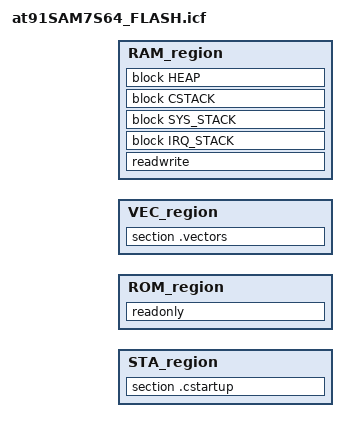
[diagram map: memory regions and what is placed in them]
/*###ICF### Section handled by ICF editor, don't touch! ****/
/*-Editor annotation file-*/
/* IcfEditorFile="$TOOLKIT_DIR$\config\ide\IcfEditor\a_v1_0.xml" */
/*-Specials-*/
define symbol __ICFEDIT_intvec_start__ = 0x00000000;
/*-Memory Regions-*/
define symbol __ICFEDIT_region_ROM_start__   = 0x100000;
define symbol __ICFEDIT_region_ROM_end__     = 0x10FFFF;
define symbol __ICFEDIT_region_RAM_start__ = 0x00200000;
define symbol __ICFEDIT_region_RAM_end__   = 0x00203FFF;
/*-Sizes-*/
define symbol __ICFEDIT_size_cstack__   = 0x200;
define symbol __ICFEDIT_size_svcstack__ = 0x200;
define symbol __ICFEDIT_size_irqstack__ = 0x200;
define symbol __ICFEDIT_size_fiqstack__ = 0x4;
define symbol __ICFEDIT_size_undstack__ = 0x4;
define symbol __ICFEDIT_size_abtstack__ = 0x4;
define symbol __ICFEDIT_size_heap__     = 0x4;
/*-Exports-*/
export symbol __ICFEDIT_region_ROM_start__;
export symbol __ICFEDIT_region_ROM_end__;
export symbol __ICFEDIT_region_RAM_start__;
export symbol __ICFEDIT_region_RAM_end__;
export symbol __ICFEDIT_size_startup__;
export symbol __ICFEDIT_size_vectors__;
export symbol __ICFEDIT_size_cstack__;
export symbol __ICFEDIT_size_sysstack__;
export symbol __ICFEDIT_size_irqstack__;
export symbol __ICFEDIT_size_heap__;
/**** End of ICF editor section. ###ICF###*/


define memory mem with size = 4G;
define region STA_region = mem:[from __ICFEDIT_region_ROM_start__ size __ICFEDIT_size_startup__];
define region ROM_region = mem:[from __ICFEDIT_region_ROM_start__+__ICFEDIT_size_startup__ to __ICFEDIT_region_ROM_end__];
define region VEC_region = mem:[from __ICFEDIT_region_RAM_start__ size __ICFEDIT_size_vectors__];
define region RAM_region = mem:[from __ICFEDIT_region_RAM_start__+__ICFEDIT_size_vectors__ to __ICFEDIT_region_RAM_end__];

define block CSTACK    with alignment = 8, size = __ICFEDIT_size_cstack__   { };
define block SYS_STACK with alignment = 8, size = __ICFEDIT_size_sysstack__ { };
define block IRQ_STACK with alignment = 8, size = __ICFEDIT_size_irqstack__ { };
define block HEAP      with alignment = 8, size = __ICFEDIT_size_heap__     { };

initialize by copy { readwrite };
initialize by copy { section .vectors };
do not initialize  { section .noinit };

place in STA_region { section .cstartup };
place in ROM_region { readonly };
place in VEC_region { section .vectors };
place in RAM_region { readwrite, block IRQ_STACK, block SYS_STACK, block CSTACK, block HEAP };

